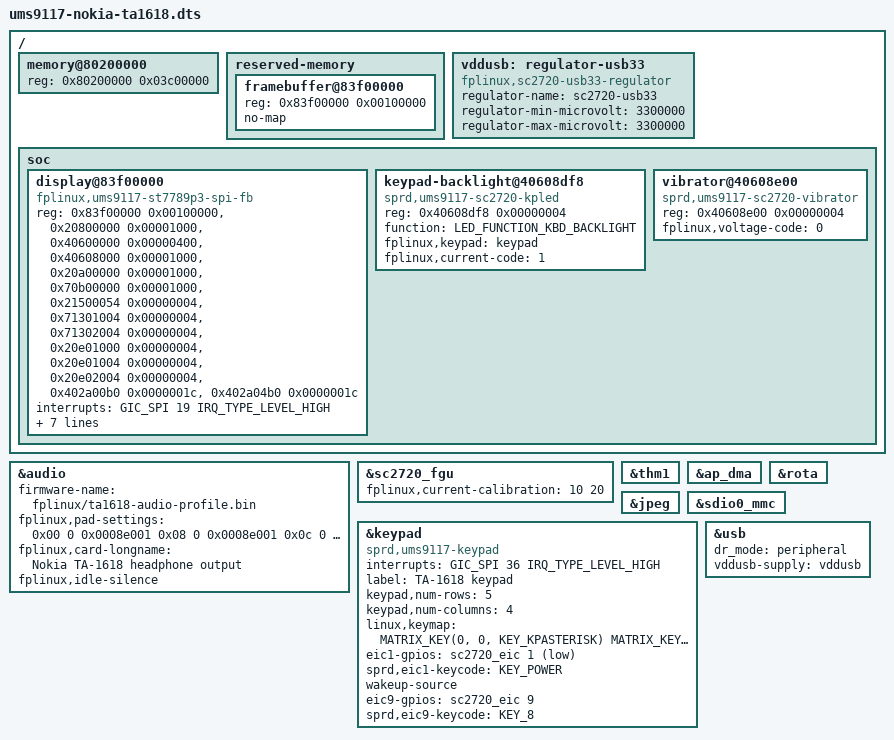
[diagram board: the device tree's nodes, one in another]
// SPDX-License-Identifier: GPL-2.0-only
/dts-v1/;

#include <dt-bindings/input/input.h>
#include <dt-bindings/gpio/gpio.h>
#include <dt-bindings/leds/common.h>
#include "ums9117.dtsi"
#include "ums9117-sc2720.dtsi"
#include "ums9117-musb-cold.dtsi"
#include "fplinux-target-identity.dtsi"
#include "nokia-ta1618-nand-readonly.dtsi"
#include "nokia-ta1618-bluetooth.dtsi"

/ {
	memory@80200000 {
		device_type = "memory";
		reg = <0x80200000 0x03c00000>;
	};

	reserved-memory {
		#address-cells = <1>;
		#size-cells = <1>;
		ranges;

		framebuffer@83f00000 {
			reg = <0x83f00000 0x00100000>;
			no-map;
		};
	};

	vddusb: regulator-usb33 {
		compatible = "fplinux,sc2720-usb33-regulator";
		regulator-name = "sc2720-usb33";
		regulator-min-microvolt = <3300000>;
		regulator-max-microvolt = <3300000>;
	};

	soc {
		display@83f00000 {
			compatible = "fplinux,ums9117-st7789p3-spi-fb";
			reg = <0x83f00000 0x00100000>,
			      <0x20800000 0x00001000>,
			      <0x40600000 0x00000400>,
			      <0x40608000 0x00001000>,
			      <0x20a00000 0x00001000>,
			      <0x70b00000 0x00001000>,
			      <0x21500054 0x00000004>,
			      <0x71301004 0x00000004>,
			      <0x71302004 0x00000004>,
			      <0x20e01000 0x00000004>,
			      <0x20e01004 0x00000004>,
			      <0x20e02004 0x00000004>,
			      <0x402a00b0 0x0000001c>,
			      <0x402a04b0 0x0000001c>;
			reg-names = "framebuffer", "lcdc", "adi-controller",
				    "analog-slave", "lcm", "spi", "spi-clock-selector",
				    "spi-reset-set", "spi-reset-clear", "ap-ahb-gate-set",
				    "ap-ahb-reset-set", "ap-ahb-reset-clear", "pinmux",
				    "pinconf";
			interrupts = <GIC_SPI 19 IRQ_TYPE_LEVEL_HIGH>;
			interrupt-names = "lcdc-done";
			sprd,aon-apb = <&aon_apb>;
			sprd,pinmux-offsets = <0 4 8 12 16 20 24>;
			sprd,pinmux-values = <0 0 0 0 0 0 0>;
			sprd,pinconf-offsets = <0 4 8 12 16 20 24>;
			sprd,pinconf-values = <
				0x00182001 0x00082046 0x00082001 0x00102004
				0x00082004 0x00102004 0x00082004
			>;
			sprd,wled-current-levels = <10 10 10 10>;
		};

		keypad-backlight@40608df8 {
			compatible = "sprd,ums9117-sc2720-kpled";
			reg = <0x40608df8 0x00000004>;
			function = LED_FUNCTION_KBD_BACKLIGHT;
			fplinux,keypad = <&keypad>;
			fplinux,current-code = <1>;
		};

		vibrator@40608e00 {
			compatible = "sprd,ums9117-sc2720-vibrator";
			reg = <0x40608e00 0x00000004>;
			fplinux,voltage-code = <0>;
		};

	};
};

#include "ums9117-ram-session.dtsi"

&audio {
	firmware-name = "fplinux/ta1618-audio-profile.bin";
	fplinux,pad-settings = <
		0x00 0 0x0008e001
		0x08 0 0x0008e001
		0x0c 0 0x0008e001
		0x1c 0 0x0008e001
	>;
	fplinux,card-longname = "Nokia TA-1618 headphone output";
	fplinux,idle-silence;
	status = "okay";
};

&sc2720_fgu {
	fplinux,current-calibration = <10 20>;
};

&thm1 {
	status = "okay";
};

&ap_dma {
	status = "okay";
};

&rota {
	status = "okay";
};

&jpeg {
	status = "okay";
};

&sdio0_mmc {
	status = "okay";
};

&keypad {
	compatible = "sprd,ums9117-keypad";
	interrupts = <GIC_SPI 36 IRQ_TYPE_LEVEL_HIGH>;
	interrupt-names = "matrix";
	status = "okay";
	label = "TA-1618 keypad";
	keypad,num-rows = <5>;
	keypad,num-columns = <4>;
	/* Exact TA-1618 scan map derived from the proven fpdoom keymap.bin. */
	linux,keymap = <
		MATRIX_KEY(0, 0, KEY_KPASTERISK) /* * */
		MATRIX_KEY(0, 1, KEY_0)
		MATRIX_KEY(0, 2, KEY_TAB) /* left soft */
		MATRIX_KEY(0, 3, KEY_KPDOT) /* # */
		MATRIX_KEY(1, 0, KEY_7)
		MATRIX_KEY(1, 1, KEY_3)
		MATRIX_KEY(1, 2, KEY_LEFT)
		MATRIX_KEY(1, 3, KEY_9)
		MATRIX_KEY(2, 0, KEY_1)
		MATRIX_KEY(2, 1, KEY_2)
		MATRIX_KEY(2, 3, KEY_6)
		MATRIX_KEY(3, 0, KEY_ENTER) /* dial */
		MATRIX_KEY(3, 1, KEY_DOWN)
		MATRIX_KEY(3, 2, KEY_ENTER) /* centre */
		MATRIX_KEY(3, 3, KEY_RIGHT)
		MATRIX_KEY(4, 0, KEY_4)
		MATRIX_KEY(4, 1, KEY_5)
		MATRIX_KEY(4, 2, KEY_UP)
		MATRIX_KEY(4, 3, KEY_BACKSPACE) /* right soft */
	>;
	eic1-gpios = <&sc2720_eic 1 GPIO_ACTIVE_LOW>;
	sprd,eic1-keycode = <KEY_POWER>;
	wakeup-source;
	eic9-gpios = <&sc2720_eic 9 GPIO_ACTIVE_HIGH>;
	sprd,eic9-keycode = <KEY_8>;
};

&usb {
	dr_mode = "peripheral";
	vddusb-supply = <&vddusb>;
	status = "okay";
};
